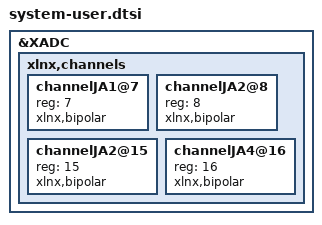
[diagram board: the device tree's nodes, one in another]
/include/ "system-conf.dtsi"
/ {

};

&XADC{
	xlnx,channels {
		#address-cells = <0x1>;
		#size-cells = <0x0>;
		channelJA1@7 {
		   reg = <7>;
		   xlnx,bipolar;
		};
		channelJA2@8 {
		   reg = <8>;
		   xlnx,bipolar;
		};
		channelJA2@15 {
		   reg = <15>;
		   xlnx,bipolar;
		};
		channelJA4@16 {
		   reg = <16>;
		   xlnx,bipolar;
		};
	};
};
